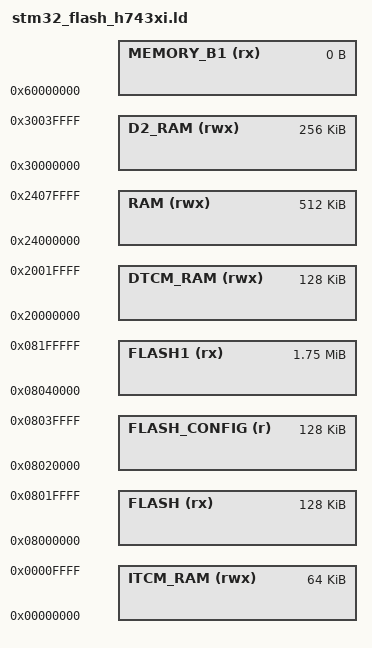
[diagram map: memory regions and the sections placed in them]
/*
*****************************************************************************
**
**  File        : stm32_flash_h743.ld
**
**  Abstract    : Linker script for STM32H743xI Device with
**                512K AXI-RAM mapped onto AXI bus on D1 domain
**                128K SRAM1 mapped on D2 domain
**                128K SRAM2 mapped on D2 domain
**                 32K SRAM3 mapped on D2 domain
**                 64K SRAM4 mapped on D3 domain
**                 64K ITCM
**                128K DTCM
**
*****************************************************************************
*/

/* Stack & Heap sizes */
_Min_Heap_Size = 0;
_Min_Stack_Size = 0x1800;

/* Entry Point */
ENTRY(Reset_Handler)

/*
0x00000000 to 0x0000FFFF   64K ITCM
0x20000000 to 0x2001FFFF  128K DTCM
0x24000000 to 0x2407FFFF  512K AXI SRAM, D1 domain, main RAM
0x30000000 to 0x3001FFFF  128K SRAM1, D2 domain, unused
0x30020000 to 0x3003FFFF  128K SRAM2, D2 domain, unused
0x30040000 to 0x30047FFF   32K SRAM3, D2 domain, unused
0x38000000 to 0x3800FFFF   64K SRAM4, D3 domain, unused
0x38800000 to 0x38800FFF    4K BACKUP SRAM, Backup domain, unused

0x08000000 to 0x081FFFFF 2048K full flash,
0x08000000 to 0x0801FFFF  128K isr vector, startup code,
0x08020000 to 0x0803FFFF  128K config,                  // FLASH_Sector_1
0x08040000 to 0x081FFFFF 1792K firmware,
*/

/* Specify the memory areas */
MEMORY
{
    FLASH (rx)        : ORIGIN = 0x08000000, LENGTH = 128K
    FLASH_CONFIG (r)  : ORIGIN = 0x08020000, LENGTH = 128K
    FLASH1 (rx)       : ORIGIN = 0x08040000, LENGTH = 1792K

    ITCM_RAM (rwx)    : ORIGIN = 0x00000000, LENGTH = 64K
    DTCM_RAM (rwx)    : ORIGIN = 0x20000000, LENGTH = 128K
    RAM (rwx)         : ORIGIN = 0x24000000, LENGTH = 512K

    D2_RAM (rwx)      : ORIGIN = 0x30000000, LENGTH = 256K /* SRAM1 + SRAM2 */

    MEMORY_B1 (rx)    : ORIGIN = 0x60000000, LENGTH = 0K
}

REGION_ALIAS("STACKRAM", DTCM_RAM)
REGION_ALIAS("FASTRAM",  DTCM_RAM)

INCLUDE "stm32_flash_h7_split.ld"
